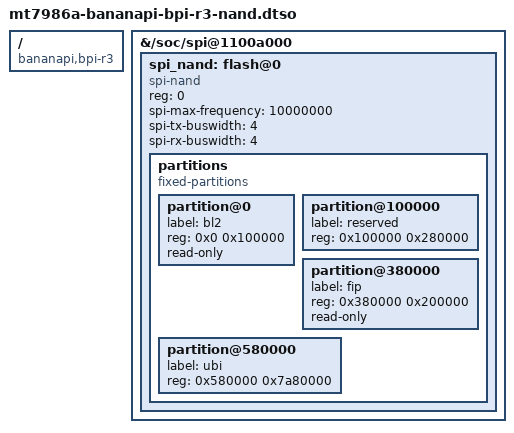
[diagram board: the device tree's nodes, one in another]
/* SPDX-License-Identifier: (GPL-2.0-only OR MIT) */
/*
 * Authors: Daniel Golle <daniel@makrotopia.org>
 *          Frank Wunderlich <frank-w@public-files.de>
 */

/dts-v1/;
/plugin/;

/ {
	compatible = "bananapi,bpi-r3", "mediatek,mt7986a";
};

&{/soc/spi@1100a000} {
	#address-cells = <1>;
	#size-cells = <0>;

	spi_nand: flash@0 {
		compatible = "spi-nand";
		reg = <0>;
		spi-max-frequency = <10000000>;
		spi-tx-buswidth = <4>;
		spi-rx-buswidth = <4>;

		partitions {
			compatible = "fixed-partitions";
			#address-cells = <1>;
			#size-cells = <1>;

			partition@0 {
				label = "bl2";
				reg = <0x0 0x100000>;
				read-only;
			};

			partition@100000 {
				label = "reserved";
				reg = <0x100000 0x280000>;
			};

			partition@380000 {
				label = "fip";
				reg = <0x380000 0x200000>;
				read-only;
			};

			partition@580000 {
				label = "ubi";
				reg = <0x580000 0x7a80000>;
			};
		};
	};
};
